# STM32GBK1CBT6 register map
File version: 1.6
CPU: CM4 r0p1, little endian, MPU, FPU, 4 interrupt priority bits
Registers are 32-bit, read-write, reset 0x0 unless marked. A register's access mark holds for its fields unless they carry their own. Offsets are from the block's base; [hi:lo] are bit positions; {n}, {i} and the like mark numbered series.

## DBGMCU — Debug support
Base 0xE0042000
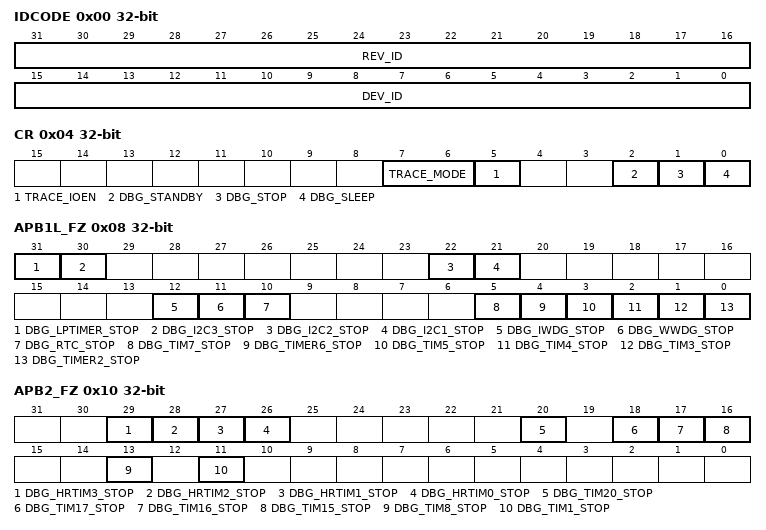
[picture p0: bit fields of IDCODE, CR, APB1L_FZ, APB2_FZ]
0x00 IDCODE ro — MCU Device ID Code Register
  [31:16] REV_ID — Revision Identifier
  [15:0] DEV_ID — Device Identifier
0x04 CR — Debug MCU Configuration Register
  [7:6] TRACE_MODE — Trace pin assignment control
  [5] TRACE_IOEN — Trace pin assignment control
  [2] DBG_STANDBY — Debug Standby Mode
  [1] DBG_STOP — Debug Stop Mode
  [0] DBG_SLEEP — Debug Sleep Mode
0x08 APB1L_FZ — APB Low Freeze Register 1
  [31] DBG_LPTIMER_STOP — LPTIM1 counter stopped when core is halted
  [30] DBG_I2C3_STOP — I2C3 SMBUS timeout mode stopped when core is halted
  [22] DBG_I2C2_STOP — I2C2 SMBUS timeout mode stopped when core is halted
  [21] DBG_I2C1_STOP — I2C1 SMBUS timeout mode stopped when core is halted
  [12] DBG_IWDG_STOP — Debug Independent Wachdog stopped when Core is halted
  [11] DBG_WWDG_STOP — Debug Window Wachdog stopped when Core is halted
  [10] DBG_RTC_STOP — Debug RTC stopped when Core is halted
  [5] DBG_TIM7_STOP — TIM7 counter stopped when core is halted
  [4] DBG_TIMER6_STOP — Debug Timer 6 stopped when Core is halted
  [3] DBG_TIM5_STOP — TIM5 counter stopped when core is halted
  [2] DBG_TIM4_STOP — TIM4 counter stopped when core is halted
  [1] DBG_TIM3_STOP — TIM3 counter stopped when core is halted
  [0] DBG_TIMER2_STOP — Debug Timer 2 stopped when Core is halted
0x0C APB1H_FZ — APB Low Freeze Register 2
  [1] DBG_I2C4_STOP
0x10 APB2_FZ — APB High Freeze Register
  [29] DBG_HRTIM3_STOP — DBG_HRTIM0_STOP
  [28] DBG_HRTIM2_STOP — DBG_HRTIM0_STOP
  [27] DBG_HRTIM1_STOP — DBG_HRTIM0_STOP
  [26] DBG_HRTIM0_STOP
  [20] DBG_TIM20_STOP — TIM20counter stopped when core is halted
  [18] DBG_TIM17_STOP — TIM17 counter stopped when core is halted
  [17] DBG_TIM16_STOP — TIM16 counter stopped when core is halted
  [16] DBG_TIM15_STOP — TIM15 counter stopped when core is halted
  [13] DBG_TIM8_STOP — TIM8 counter stopped when core is halted
  [11] DBG_TIM1_STOP — TIM1 counter stopped when core is halted

## RNG — Random number generator
Base 0x50060800
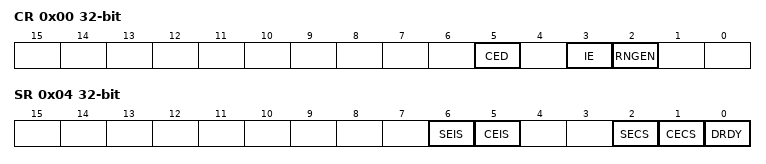
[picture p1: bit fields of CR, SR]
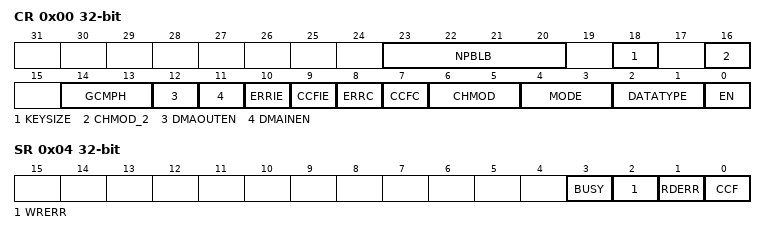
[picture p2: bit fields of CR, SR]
0x00 CR — control register
  [5] CED — Clock error detection
  [3] IE — Interrupt enable
  [2] RNGEN — Random number generator enable
0x04 SR access per field — status register
  [6] SEIS rw — Seed error interrupt status
  [5] CEIS rw — Clock error interrupt status
  [2] SECS ro — Seed error current status
  [1] CECS ro — Clock error current status
  [0] DRDY ro — Data ready
0x08 DR ro — data register
  [31:0] RNDATA — Random data

## AES — Advanced encryption standard hardware accelerator
Base 0x50060000
0x00 CR — control register
  [23:20] NPBLB
  [18] KEYSIZE
  [16] CHMOD_2
  [14:13] GCMPH
  [12] DMAOUTEN — Enable DMA management of data output phase
  [11] DMAINEN — Enable DMA management of data input phase
  [10] ERRIE — Error interrupt enable
  [9] CCFIE — CCF flag interrupt enable
  [8] ERRC — Error clear
  [7] CCFC — Computation Complete Flag Clear
  [6:5] CHMOD — AES chaining mode
  [4:3] MODE — AES operating mode
  [2:1] DATATYPE — Data type selection (for data in and data out to/from the cryptographic block)
  [0] EN — AES enable
0x04 SR ro — status register
  [3] BUSY
  [2] WRERR — Write error flag
  [1] RDERR — Read error flag
  [0] CCF — Computation complete flag
0x08 DINR — data input register
  [31:0] AES_DINR — Data Input Register
0x0C DOUTR ro — data output register
  [31:0] AES_DOUTR — Data output register
0x10 KEYR0 — key register 0
  [31:0] AES_KEYR0 — Data Output Register (LSB key [31:0])
0x14 KEYR1 — key register 1
  [31:0] AES_KEYR1 — AES key register (key [63:32])
0x18 KEYR2 — key register 2
  [31:0] AES_KEYR2 — AES key register (key [95:64])
0x1C KEYR3 — key register 3
  [31:0] AES_KEYR3 — AES key register (MSB key [127:96])
0x20 IVR0 — initialization vector register 0
  [31:0] AES_IVR0 — initialization vector register (LSB IVR [31:0])
0x24 IVR1 — initialization vector register 1
  [31:0] AES_IVR1 — Initialization Vector Register (IVR [63:32])
0x28 IVR2 — initialization vector register 2
  [31:0] AES_IVR2 — Initialization Vector Register (IVR [95:64])
0x2C IVR3 — initialization vector register 3
  [31:0] AES_IVR3 — Initialization Vector Register (MSB IVR [127:96])
{0x20+4i} KEYR{i} (i=4..7) — key register {i}
  [31:0] KEY — AES key
{0x40+4i} SUSP{i}R (i=0..7) — suspend registers
  [31:0] SUSP — AES suspend
